# STM32F7x5 register map
File version: 1.4
CPU: CM7 r0p0, little endian, no MPU, no FPU, 3 interrupt priority bits
Registers are 32-bit, read-write, reset 0x0 unless marked. A register's access mark holds for its fields unless they carry their own. Offsets are from the block's base; [hi:lo] are bit positions.

## PWR — Power control
Base 0x40007000
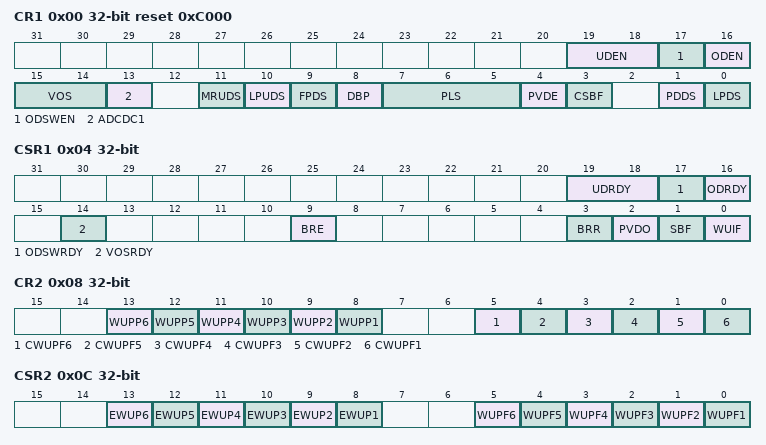
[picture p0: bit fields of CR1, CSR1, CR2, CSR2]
0x00 CR1 reset 0xC000 — power control register
  [19:18] UDEN — Under-drive enable in stop mode
  [17] ODSWEN — Over-drive switching enabled
  [16] ODEN — Over-drive enable
  [15:14] VOS — Regulator voltage scaling output selection
  [13] ADCDC1
  [11] MRUDS — Main regulator in deepsleep under-drive mode
  [10] LPUDS — Low-power regulator in deepsleep under-drive mode
  [9] FPDS — Flash power down in Stop mode
  [8] DBP — Disable backup domain write protection
  [7:5] PLS — PVD level selection
  [4] PVDE — Power voltage detector enable
  [3] CSBF — Clear standby flag
  [1] PDDS — Power down deepsleep
  [0] LPDS — Low-power deep sleep
0x04 CSR1 access per field — power control/status register
  [19:18] UDRDY rw — Under-drive ready flag
  [17] ODSWRDY rw — Over-drive mode switching ready
  [16] ODRDY rw — Over-drive mode ready
  [14] VOSRDY rw — Regulator voltage scaling output selection ready bit
  [9] BRE rw — Backup regulator enable
  [3] BRR ro — Backup regulator ready
  [2] PVDO ro — PVD output
  [1] SBF ro — Standby flag
  [0] WUIF ro — Wakeup internal flag
0x08 CR2 access per field — power control register
  [13] WUPP6 rw — Wakeup pin polarity bit for PI11
  [12] WUPP5 rw — Wakeup pin polarity bit for PI8
  [11] WUPP4 rw — Wakeup pin polarity bit for PC13
  [10] WUPP3 rw — Wakeup pin polarity bit for PC1
  [9] WUPP2 rw — Wakeup pin polarity bit for PA2
  [8] WUPP1 rw — Wakeup pin polarity bit for PA0
  [5] CWUPF6 ro — Clear Wakeup Pin flag for PI11
  [4] CWUPF5 ro — Clear Wakeup Pin flag for PI8
  [3] CWUPF4 ro — Clear Wakeup Pin flag for PC13
  [2] CWUPF3 ro — Clear Wakeup Pin flag for PC1
  [1] CWUPF2 ro — Clear Wakeup Pin flag for PA2
  [0] CWUPF1 ro — Clear Wakeup Pin flag for PA0
0x0C CSR2 access per field — power control/status register
  [13] EWUP6 rw — Enable Wakeup pin for PI11
  [12] EWUP5 rw — Enable Wakeup pin for PI8
  [11] EWUP4 rw — Enable Wakeup pin for PC13
  [10] EWUP3 rw — Enable Wakeup pin for PC1
  [9] EWUP2 rw — Enable Wakeup pin for PA2
  [8] EWUP1 rw — Enable Wakeup pin for PA0
  [5] WUPF6 ro — Wakeup Pin flag for PI11
  [4] WUPF5 ro — Wakeup Pin flag for PI8
  [3] WUPF4 ro — Wakeup Pin flag for PC13
  [2] WUPF3 ro — Wakeup Pin flag for PC1
  [1] WUPF2 ro — Wakeup Pin flag for PA2
  [0] WUPF1 ro — Wakeup Pin flag for PA0

## IWDG — Independent watchdog
Base 0x40003000
0x00 KR wo — Key register
  [15:0] KEY — Key value (write only, read 0000h)
0x04 PR — Prescaler register
  [2:0] PR — Prescaler divider
0x08 RLR reset 0xFFF — Reload register
  [11:0] RL — Watchdog counter reload value
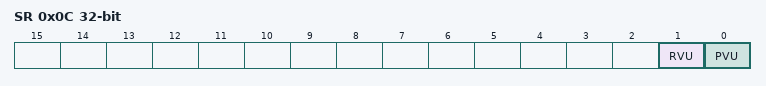
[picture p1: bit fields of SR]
0x0C SR ro — Status register
  [1] RVU — Watchdog counter reload value update
  [0] PVU — Watchdog prescaler value update
0x10 WINR — Window register
  [11:0] WIN — Watchdog counter window value

## WWDG — Window watchdog
Base 0x40002C00
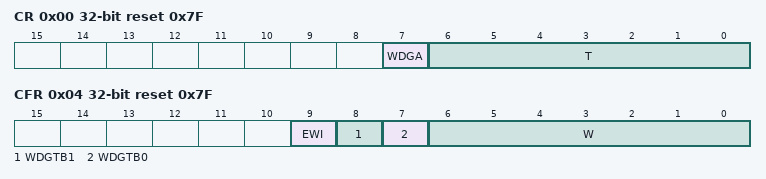
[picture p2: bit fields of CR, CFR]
0x00 CR reset 0x7F — Control register
  [7] WDGA — Activation bit
  [6:0] T — 7-bit counter (MSB to LSB)
0x04 CFR reset 0x7F — Configuration register
  [9] EWI — Early wakeup interrupt
  [8] WDGTB1 — Timer base
  [7] WDGTB0 — Timer base
  [6:0] W — 7-bit window value
0x08 SR — Status register
  [0] EWIF — Early wakeup interrupt flag

## C_ADC — Common ADC registers
Base 0x40012300
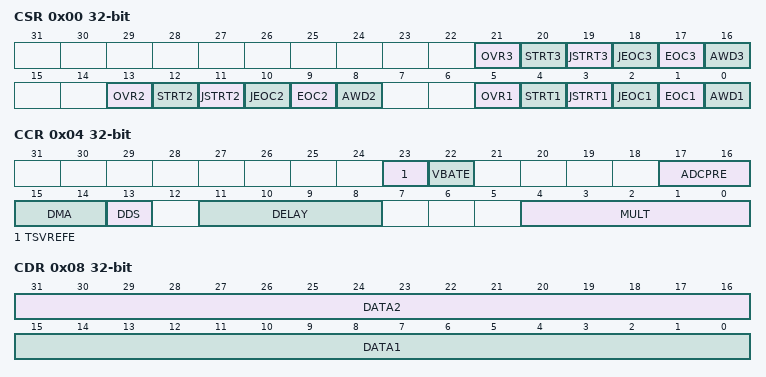
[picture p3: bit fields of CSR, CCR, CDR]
0x00 CSR ro — ADC Common status register
  [21] OVR3 — Overrun flag of ADC3
  [20] STRT3 — Regular channel Start flag of ADC 3
  [19] JSTRT3 — Injected channel Start flag of ADC 3
  [18] JEOC3 — Injected channel end of conversion of ADC 3
  [17] EOC3 — End of conversion of ADC 3
  [16] AWD3 — Analog watchdog flag of ADC 3
  [13] OVR2 — Overrun flag of ADC 2
  [12] STRT2 — Regular channel Start flag of ADC 2
  [11] JSTRT2 — Injected channel Start flag of ADC 2
  [10] JEOC2 — Injected channel end of conversion of ADC 2
  [9] EOC2 — End of conversion of ADC 2
  [8] AWD2 — Analog watchdog flag of ADC 2
  [5] OVR1 — Overrun flag of ADC 1
  [4] STRT1 — Regular channel Start flag of ADC 1
  [3] JSTRT1 — Injected channel Start flag of ADC 1
  [2] JEOC1 — Injected channel end of conversion of ADC 1
  [1] EOC1 — End of conversion of ADC 1
  [0] AWD1 — Analog watchdog flag of ADC 1
0x04 CCR — ADC common control register
  [23] TSVREFE — Temperature sensor and VREFINT enable
  [22] VBATE — VBAT enable
  [17:16] ADCPRE — ADC prescaler
  [15:14] DMA — Direct memory access mode for multi ADC mode
  [13] DDS — DMA disable selection for multi-ADC mode
  [11:8] DELAY — Delay between 2 sampling phases
  [4:0] MULT — Multi ADC mode selection
0x08 CDR ro — ADC common regular data register for dual and triple modes
  [31:16] DATA2 — 2nd data item of a pair of regular conversions
  [15:0] DATA1 — 1st data item of a pair of regular conversions
